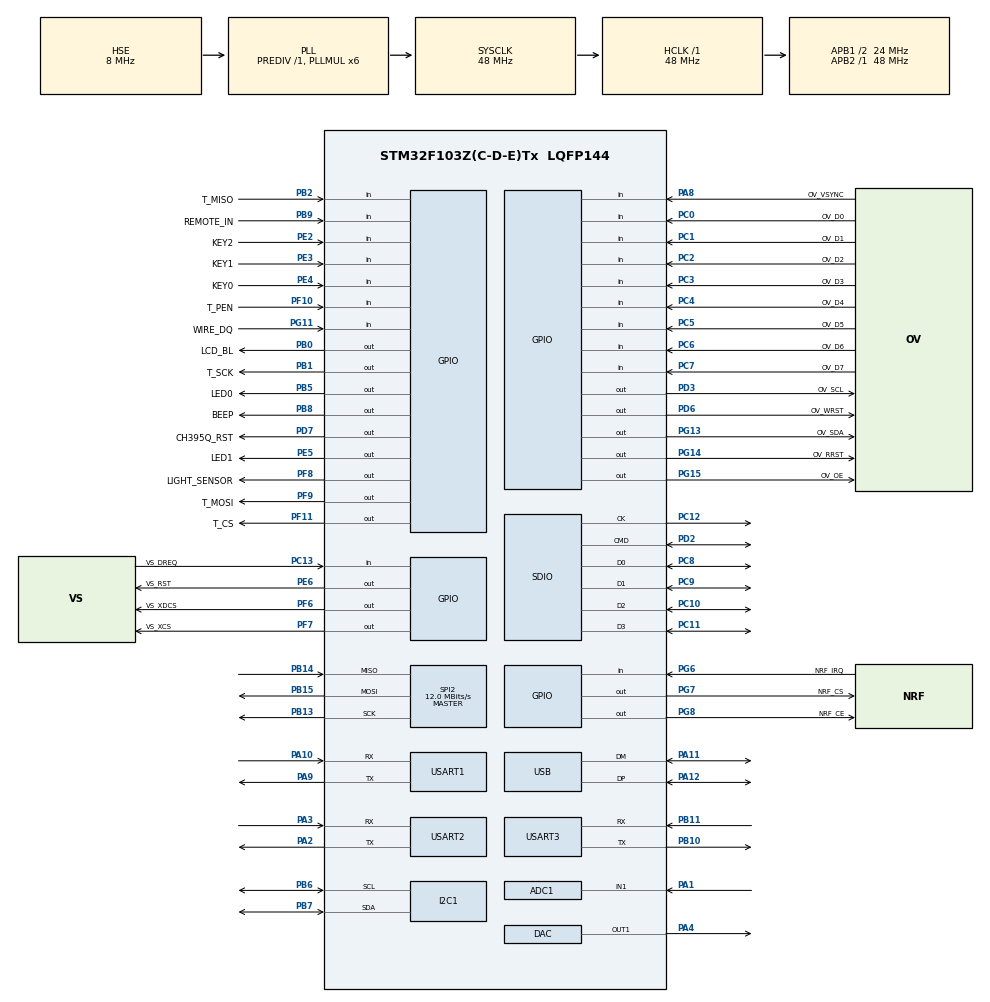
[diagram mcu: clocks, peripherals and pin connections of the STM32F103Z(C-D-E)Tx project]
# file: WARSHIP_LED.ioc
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ADC1.Channel-0\#ChannelRegularConversion=ADC_CHANNEL_1
ADC1.NbrOfConversionFlag=1
ADC1.Rank-0\#ChannelRegularConversion=1
ADC1.SamplingTime-0\#ChannelRegularConversion=ADC_SAMPLETIME_1CYCLE_5
ADC1.master=1
Mcu.Family=STM32F1
Mcu.Name=STM32F103Z(C-D-E)Tx
Mcu.Package=LQFP144
NVIC.PriorityGroup=NVIC_PRIORITYGROUP_4
OSC_IN.Mode=HSE-External-Oscillator
OSC_IN.Signal=RCC_OSC_IN
OSC_OUT.Mode=HSE-External-Oscillator
OSC_OUT.Signal=RCC_OSC_OUT
PA1.Signal=ADCx_IN1
PA10.Mode=Asynchronous
PA10.Signal=USART1_RX
PA11.Mode=Device
PA11.Signal=USB_DM
PA12.Mode=Device
PA12.Signal=USB_DP
PA13.Mode=JTAG_5_pins
PA13.Signal=SYS_JTMS-SWDIO
PA14.Mode=JTAG_5_pins
PA14.Signal=SYS_JTCK-SWCLK
PA15.Mode=JTAG_5_pins
PA15.Signal=SYS_JTDI
PA2.Mode=Asynchronous
PA2.Signal=USART2_TX
PA3.Mode=Asynchronous
PA3.Signal=USART2_RX
PA4.Signal=COMP_DAC1_group
PA5.Signal=SPI1_SCK
PA6.Signal=SPI1_MISO
PA7.Signal=SPI1_MOSI
PA8.GPIO_Label=OV_VSYNC
PA8.Signal=GPIO_Input
PA9.Mode=Asynchronous
PA9.Signal=USART1_TX
PB0.GPIO_Label=LCD_BL
PB0.Signal=GPIO_Output
PB1.GPIO_Label=T_SCK
PB1.Signal=GPIO_Output
PB10.Mode=Asynchronous
PB10.Signal=USART3_TX
PB11.Mode=Asynchronous
PB11.Signal=USART3_RX
PB12.Signal=SPI2_NSS
PB13.Mode=Full_Duplex_Master
PB13.Signal=SPI2_SCK
PB14.Mode=Full_Duplex_Master
PB14.Signal=SPI2_MISO
PB15.Mode=Full_Duplex_Master
PB15.Signal=SPI2_MOSI
PB2.GPIO_Label=T_MISO
PB2.Signal=GPIO_Input
PB3.Mode=JTAG_5_pins
PB3.Signal=SYS_JTDO-TRACESWO
PB4.Mode=JTAG_5_pins
PB4.Signal=SYS_NJTRST
PB5.GPIO_Label=LED0
PB5.Signal=GPIO_Output
PB6.Mode=I2C
PB6.Signal=I2C1_SCL
PB7.Mode=I2C
PB7.Signal=I2C1_SDA
PB8.GPIO_Label=BEEP
PB8.Signal=GPIO_Output
PB9.GPIO_Label=REMOTE_IN
PB9.Signal=GPIO_Input
PC0.GPIO_Label=OV_D0
PC0.Signal=GPIO_Input
PC1.GPIO_Label=OV_D1
PC1.Signal=GPIO_Input
PC10.Mode=SD_4_bits_Wide_bus
PC10.Signal=SDIO_D2
PC11.Mode=SD_4_bits_Wide_bus
PC11.Signal=SDIO_D3
PC12.Mode=SD_4_bits_Wide_bus
PC12.Signal=SDIO_CK
PC13-TAMPER-RTC.GPIO_Label=VS_DREQ
PC13-TAMPER-RTC.Signal=GPIO_Input
PC14-OSC32_IN.Mode=LSE-External-Oscillator
PC14-OSC32_IN.Signal=RCC_OSC32_IN
PC15-OSC32_OUT.Mode=LSE-External-Oscillator
PC15-OSC32_OUT.Signal=RCC_OSC32_OUT
PC2.GPIO_Label=OV_D2
PC2.Signal=GPIO_Input
PC3.GPIO_Label=OV_D3
PC3.Signal=GPIO_Input
PC4.GPIO_Label=OV_D4
PC4.Signal=GPIO_Input
PC5.GPIO_Label=OV_D5
PC5.Signal=GPIO_Input
PC6.GPIO_Label=OV_D6
PC6.Signal=GPIO_Input
PC7.GPIO_Label=OV_D7
PC7.Signal=GPIO_Input
PC8.Mode=SD_4_bits_Wide_bus
PC8.Signal=SDIO_D0
PC9.Mode=SD_4_bits_Wide_bus
PC9.Signal=SDIO_D1
PD0.Signal=FSMC_D2_DA2
PD1.Signal=FSMC_D3_DA3
PD10.Signal=FSMC_D15_DA15
PD11.Signal=FSMC_A16_CLE
PD12.Signal=FSMC_A17_ALE
PD13.Signal=FSMC_A18
PD14.Signal=FSMC_D0_DA0
PD15.Signal=FSMC_D1_DA1
PD2.Mode=SD_4_bits_Wide_bus
PD2.Signal=SDIO_CMD
PD3.GPIO_Label=OV_SCL
PD3.GPIO_ModeDefaultOutputPP=GPIO_MODE_OUTPUT_OD
PD3.GPIO_PuPd=GPIO_NOPULL
PD3.Signal=GPIO_Output
PD4.Signal=FSMC_NOE
PD5.Signal=FSMC_NWE
PD6.GPIO_Label=OV_WRST
PD6.Signal=GPIO_Output
PD7.GPIO_Label=CH395Q_RST
PD7.Signal=GPIO_Output
PD8.Signal=FSMC_D13_DA13
PD9.Signal=FSMC_D14_DA14
PE0.Signal=FSMC_NBL0
PE1.Signal=FSMC_NBL1
PE10.Signal=FSMC_D7_DA7
PE11.Signal=FSMC_D8_DA8
PE12.Signal=FSMC_D9_DA9
PE13.Signal=FSMC_D10_DA10
PE14.Signal=FSMC_D11_DA11
PE15.Signal=FSMC_D12_DA12
PE2.GPIO_Label=KEY2
PE2.Signal=GPIO_Input
PE3.GPIO_Label=KEY1
PE3.Signal=GPIO_Input
PE4.GPIO_Label=KEY0
PE4.Signal=GPIO_Input
PE5.GPIO_Label=LED1
PE5.Signal=GPIO_Output
PE6.GPIO_Label=VS_RST
PE6.Signal=GPIO_Output
PE7.Signal=FSMC_D4_DA4
PE8.Signal=FSMC_D5_DA5
PE9.Signal=FSMC_D6_DA6
PF0.Signal=FSMC_A0
PF1.Signal=FSMC_A1
PF10.GPIO_Label=T_PEN
PF10.Signal=GPIO_Input
PF11.GPIO_Label=T_CS
PF11.Signal=GPIO_Output
PF12.Signal=FSMC_A6
PF13.Signal=FSMC_A7
PF14.Signal=FSMC_A8
PF15.Signal=FSMC_A9
PF2.Signal=FSMC_A2
PF3.Signal=FSMC_A3
PF4.Signal=FSMC_A4
PF5.Signal=FSMC_A5
PF6.GPIO_Label=VS_XDCS
PF6.Signal=GPIO_Output
PF7.GPIO_Label=VS_XCS
PF7.Signal=GPIO_Output
PF8.GPIO_Label=LIGHT_SENSOR
PF8.Signal=GPIO_Output
PF9.GPIO_Label=T_MOSI
PF9.Signal=GPIO_Output
PG0.Signal=FSMC_A10
PG1.Signal=FSMC_A11
PG10.Signal=FSMC_NE3
PG11.GPIO_Label=WIRE_DQ
PG11.Signal=GPIO_Input
PG12.Signal=FSMC_NE4
PG13.GPIO_Label=OV_SDA
PG13.GPIO_ModeDefaultOutputPP=GPIO_MODE_OUTPUT_OD
PG13.GPIO_PuPd=GPIO_NOPULL
PG13.Signal=GPIO_Output
PG14.GPIO_Label=OV_RRST
PG14.Signal=GPIO_Output
PG15.GPIO_Label=OV_OE
PG15.Signal=GPIO_Output
PG2.Signal=FSMC_A12
PG3.Signal=FSMC_A13
PG4.Signal=FSMC_A14
PG5.Signal=FSMC_A15
PG6.GPIO_Label=NRF_IRQ
PG6.Signal=GPIO_Input
PG7.GPIO_Label=NRF_CS
PG7.Signal=GPIO_Output
PG8.GPIO_Label=NRF_CE
PG8.Signal=GPIO_Output
PG9.Signal=FSMC_NE2
ProjectManager.HeapSize=0x200
ProjectManager.StackSize=0x400
ProjectManager.TargetToolchain=CMake
RCC.ADCPresc=RCC_ADCPCLK2_DIV4
RCC.AHBFreq_Value=48000000
RCC.APB1CLKDivider=RCC_HCLK_DIV2
RCC.APB1Freq_Value=24000000
RCC.APB1TimFreq_Value=48000000
RCC.APB2Freq_Value=48000000
RCC.APB2TimFreq_Value=48000000
RCC.HCLKFreq_Value=48000000
RCC.PLLMUL=RCC_PLL_MUL6
RCC.PLLSourceVirtual=RCC_PLLSOURCE_HSE
RCC.SYSCLKFreq_VALUE=48000000
RCC.SYSCLKSource=RCC_SYSCLKSOURCE_PLLCLK
RCC.USBFreq_Value=48000000
SH.ADCx_IN1.0=ADC1_IN1,IN1
SH.COMP_DAC1_group.0=DAC_OUT1,DAC_OUT1
SH.FSMC_A0.0=FSMC_A0
SH.FSMC_A1.0=FSMC_A1
SH.FSMC_A10.0=FSMC_A10
SH.FSMC_A11.0=FSMC_A11
SH.FSMC_A12.0=FSMC_A12
SH.FSMC_A13.0=FSMC_A13
SH.FSMC_A14.0=FSMC_A14
SH.FSMC_A15.0=FSMC_A15
SH.FSMC_A16_CLE.0=FSMC_A16
SH.FSMC_A17_ALE.0=FSMC_A17
SH.FSMC_A18.0=FSMC_A18
SH.FSMC_A2.0=FSMC_A2
SH.FSMC_A3.0=FSMC_A3
SH.FSMC_A4.0=FSMC_A4
SH.FSMC_A5.0=FSMC_A5
SH.FSMC_A6.0=FSMC_A6
SH.FSMC_A7.0=FSMC_A7
SH.FSMC_A8.0=FSMC_A8
SH.FSMC_A9.0=FSMC_A9
SH.FSMC_D0_DA0.0=FSMC_D0
SH.FSMC_D10_DA10.0=FSMC_D10
SH.FSMC_D11_DA11.0=FSMC_D11
SH.FSMC_D12_DA12.0=FSMC_D12
SH.FSMC_D13_DA13.0=FSMC_D13
SH.FSMC_D14_DA14.0=FSMC_D14
SH.FSMC_D15_DA15.0=FSMC_D15
SH.FSMC_D1_DA1.0=FSMC_D1
SH.FSMC_D2_DA2.0=FSMC_D2
SH.FSMC_D3_DA3.0=FSMC_D3
SH.FSMC_D4_DA4.0=FSMC_D4
SH.FSMC_D5_DA5.0=FSMC_D5
SH.FSMC_D6_DA6.0=FSMC_D6
SH.FSMC_D7_DA7.0=FSMC_D7
SH.FSMC_D8_DA8.0=FSMC_D8
SH.FSMC_D9_DA9.0=FSMC_D9
SH.FSMC_NBL0.0=FSMC_NBL0
SH.FSMC_NBL1.0=FSMC_NBL1
SH.FSMC_NOE.0=FSMC_NOE
SH.FSMC_NWE.0=FSMC_NWE
SPI2.CalculateBaudRate=12.0 MBits/s
SPI2.Direction=SPI_DIRECTION_2LINES
SPI2.Mode=SPI_MODE_MASTER
SPI2.VirtualType=VM_MASTER
USART1.VirtualMode=VM_ASYNC
USART2.VirtualMode=VM_ASYNC
USART3.VirtualMode=VM_ASYNC
VP_RTC_VS_RTC_Activate.Mode=RTC_Enabled
board=custom

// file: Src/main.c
/* USER CODE BEGIN Header */
/**
  ******************************************************************************
  * @file           : main.c
  * @brief          : Main program body
  ******************************************************************************
  * @attention
  *
  * Copyright (c) 2025 STMicroelectronics.
  * All rights reserved.
  *
  * This software is licensed under terms that can be found in the LICENSE file
  * in the root directory of this software component.
  * If no LICENSE file comes with this software, it is provided AS-IS.
  *
  ******************************************************************************
  */
/* USER CODE END Header */
#include "main.h"
#include "adc.h"
#include "dac.h"
#include "i2c.h"
#include "rtc.h"
#include "sdio.h"
#include "spi.h"
#include "usart.h"
#include "usb.h"
#include "gpio.h"

void SystemClock_Config(void);

int main(void)
{

  /* MCU Configuration--------------------------------------------------------*/

  /* Reset of all peripherals, Initializes the Flash interface and the Systick. */
  HAL_Init();

  /* Configure the system clock */
  SystemClock_Config();

  /* Initialize all configured peripherals */
  MX_GPIO_Init();
  MX_RTC_Init();
  MX_ADC1_Init();
  MX_DAC_Init();
  MX_I2C1_Init();
  MX_SDIO_SD_Init();
  MX_SPI2_Init();
  MX_USART1_UART_Init();
  MX_USART2_UART_Init();
  MX_USART3_UART_Init();
  MX_USB_PCD_Init();

  /* Infinite loop */
  while (1)
  {

    /* USER CODE BEGIN 3 */

    // HAL_Delay(500);
    // HAL_GPIO_TogglePin(LED0_GPIO_Port, LED0_Pin);
    // HAL_GPIO_TogglePin(LED1_GPIO_Port, LED1_Pin);

    HAL_GPIO_WritePin(LED0_GPIO_Port, LED0_Pin, GPIO_PIN_SET);
    HAL_GPIO_WritePin(LED1_GPIO_Port, LED1_Pin, GPIO_PIN_SET);
    HAL_Delay(500);
    HAL_GPIO_WritePin(LED0_GPIO_Port, LED0_Pin, GPIO_PIN_RESET);
    HAL_GPIO_WritePin(LED1_GPIO_Port, LED1_Pin, GPIO_PIN_RESET);
    HAL_Delay(500);
  }
  /* USER CODE END 3 */
}

void SystemClock_Config(void)
{
  RCC_OscInitTypeDef RCC_OscInitStruct = {0};
  RCC_ClkInitTypeDef RCC_ClkInitStruct = {0};
  RCC_PeriphCLKInitTypeDef PeriphClkInit = {0};

  /** Initializes the RCC Oscillators according to the specified parameters
  * in the RCC_OscInitTypeDef structure.
  */
  RCC_OscInitStruct.OscillatorType = RCC_OSCILLATORTYPE_LSI|RCC_OSCILLATORTYPE_HSE;
  RCC_OscInitStruct.HSEState = RCC_HSE_ON;
  RCC_OscInitStruct.HSEPredivValue = RCC_HSE_PREDIV_DIV1;
  RCC_OscInitStruct.HSIState = RCC_HSI_ON;
  RCC_OscInitStruct.LSIState = RCC_LSI_ON;
  RCC_OscInitStruct.PLL.PLLState = RCC_PLL_ON;
  RCC_OscInitStruct.PLL.PLLSource = RCC_PLLSOURCE_HSE;
  RCC_OscInitStruct.PLL.PLLMUL = RCC_PLL_MUL6;
  if (HAL_RCC_OscConfig(&RCC_OscInitStruct) != HAL_OK)
  {
    Error_Handler();
  }

  /** Initializes the CPU, AHB and APB buses clocks
  */
  RCC_ClkInitStruct.ClockType = RCC_CLOCKTYPE_HCLK|RCC_CLOCKTYPE_SYSCLK
                              |RCC_CLOCKTYPE_PCLK1|RCC_CLOCKTYPE_PCLK2;
  RCC_ClkInitStruct.SYSCLKSource = RCC_SYSCLKSOURCE_PLLCLK;
  RCC_ClkInitStruct.AHBCLKDivider = RCC_SYSCLK_DIV1;
  RCC_ClkInitStruct.APB1CLKDivider = RCC_HCLK_DIV2;
  RCC_ClkInitStruct.APB2CLKDivider = RCC_HCLK_DIV1;

  if (HAL_RCC_ClockConfig(&RCC_ClkInitStruct, FLASH_LATENCY_1) != HAL_OK)
  {
    Error_Handler();
  }
  PeriphClkInit.PeriphClockSelection = RCC_PERIPHCLK_RTC|RCC_PERIPHCLK_ADC
                              |RCC_PERIPHCLK_USB;
  PeriphClkInit.RTCClockSelection = RCC_RTCCLKSOURCE_LSI;
  PeriphClkInit.AdcClockSelection = RCC_ADCPCLK2_DIV4;
  PeriphClkInit.UsbClockSelection = RCC_USBCLKSOURCE_PLL;
  if (HAL_RCCEx_PeriphCLKConfig(&PeriphClkInit) != HAL_OK)
  {
    Error_Handler();
  }
}

void Error_Handler(void)
{
  __disable_irq();
  while (1)
  {
  }
}
